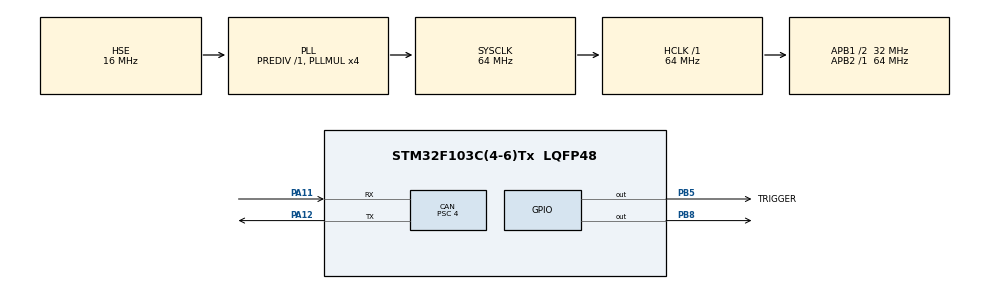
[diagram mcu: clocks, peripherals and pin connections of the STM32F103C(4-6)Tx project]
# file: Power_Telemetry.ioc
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CAN.BS1=CAN_BS1_6TQ
CAN.CalculateBaudRate=1000000
CAN.CalculateTimeBit=1000
CAN.CalculateTimeQuantum=125.0
CAN.Prescaler=4
Mcu.Family=STM32F1
Mcu.Name=STM32F103C(4-6)Tx
Mcu.Package=LQFP48
NVIC.PriorityGroup=NVIC_PRIORITYGROUP_4
PA11.Mode=CAN_Activate
PA11.Signal=CAN_RX
PA12.Mode=CAN_Activate
PA12.Signal=CAN_TX
PB5.GPIO_Label=TRIGGER
PB5.Signal=GPIO_Output
PB8.Signal=GPIO_Output
PD0-OSC_IN.Mode=HSE-External-Oscillator
PD0-OSC_IN.Signal=RCC_OSC_IN
PD1-OSC_OUT.Mode=HSE-External-Oscillator
PD1-OSC_OUT.Signal=RCC_OSC_OUT
ProjectManager.HeapSize=0x200
ProjectManager.StackSize=0x400
ProjectManager.TargetToolchain=STM32CubeIDE
RCC.AHBFreq_Value=64000000
RCC.APB1CLKDivider=RCC_HCLK_DIV2
RCC.APB1Freq_Value=32000000
RCC.APB1TimFreq_Value=64000000
RCC.APB2Freq_Value=64000000
RCC.APB2TimFreq_Value=64000000
RCC.DATA_CACHE_ENABLE=1
RCC.HCLKFreq_Value=64000000
RCC.HSE_VALUE=16000000
RCC.INSTRUCTION_CACHE_ENABLE=1
RCC.PLLMUL=RCC_PLL_MUL4
RCC.PLLSourceVirtual=RCC_PLLSOURCE_HSE
RCC.SYSCLKFreq_VALUE=64000000
RCC.SYSCLKSource=RCC_SYSCLKSOURCE_PLLCLK
RCC.USBFreq_Value=64000000
VP_SYS_VS_ND.Mode=No_Debug
board=custom

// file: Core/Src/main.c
/* USER CODE BEGIN Header */
/**
  ******************************************************************************
  * @file           : main.c
  * @brief          : Main program body
  ******************************************************************************
  * @attention
  *
  * Copyright (c) 2025 STMicroelectronics.
  * All rights reserved.
  *
  * This software is licensed under terms that can be found in the LICENSE file
  * in the root directory of this software component.
  * If no LICENSE file comes with this software, it is provided AS-IS.
  *
  ******************************************************************************
  */
/* USER CODE END Header */
#include "main.h"

CAN_HandleTypeDef hcan;

/* USER CODE BEGIN PV */
uint32_t lastTriggerTime = 0;
uint8_t triggerState = 0;  // 0 = LOW (spento), 1 = HIGH (acceso)
/* USER CODE END PV */

void SystemClock_Config(void);
static void MX_GPIO_Init(void);
static void MX_CAN_Init(void);

int main(void)
{

  /* MCU Configuration--------------------------------------------------------*/

  /* Reset of all peripherals, Initializes the Flash interface and the Systick. */
  HAL_Init();

  /* Configure the system clock */
  SystemClock_Config();

  /* Initialize all configured peripherals */
  MX_GPIO_Init();
  MX_CAN_Init();

  /* Infinite loop */
  while (1)
  {

    /* USER CODE BEGIN 3 */

    // Controlla se è passato 1 secondo dall'ultimo cambio di stato
    if (HAL_GetTick() - lastTriggerTime >= 1000)
    {
      // Cambia lo stato del pin TRIGGER ogni secondo
      if (triggerState == 0)
      {
        // Accendi il pin (HIGH) per 1 secondo
        //HAL_GPIO_WritePin(TRIGGER_GPIO_Port, TRIGGER_Pin, GPIO_PIN_SET);
        HAL_GPIO_WritePin(LED_GPIO_Port, LED_Pin, GPIO_PIN_SET);
        triggerState = 1;
      }
      else
      {
        // Spegni il pin (LOW) per 1 secondo
        //HAL_GPIO_WritePin(TRIGGER_GPIO_Port, TRIGGER_Pin, GPIO_PIN_RESET);
        HAL_GPIO_WritePin(LED_GPIO_Port, LED_Pin, GPIO_PIN_RESET);
        triggerState = 0;
      }

      // Aggiorna il tempo dell'ultimo cambio di stato
      lastTriggerTime = HAL_GetTick();
    }
  }
  /* USER CODE END 3 */
}

void SystemClock_Config(void)
{
  RCC_OscInitTypeDef RCC_OscInitStruct = {0};
  RCC_ClkInitTypeDef RCC_ClkInitStruct = {0};

  /** Initializes the RCC Oscillators according to the specified parameters
  * in the RCC_OscInitTypeDef structure.
  */
  RCC_OscInitStruct.OscillatorType = RCC_OSCILLATORTYPE_HSE;
  RCC_OscInitStruct.HSEState = RCC_HSE_ON;
  RCC_OscInitStruct.HSEPredivValue = RCC_HSE_PREDIV_DIV1;
  RCC_OscInitStruct.HSIState = RCC_HSI_ON;
  RCC_OscInitStruct.PLL.PLLState = RCC_PLL_ON;
  RCC_OscInitStruct.PLL.PLLSource = RCC_PLLSOURCE_HSE;
  RCC_OscInitStruct.PLL.PLLMUL = RCC_PLL_MUL4;
  if (HAL_RCC_OscConfig(&RCC_OscInitStruct) != HAL_OK)
  {
    Error_Handler();
  }

  /** Initializes the CPU, AHB and APB buses clocks
  */
  RCC_ClkInitStruct.ClockType = RCC_CLOCKTYPE_HCLK|RCC_CLOCKTYPE_SYSCLK
                              |RCC_CLOCKTYPE_PCLK1|RCC_CLOCKTYPE_PCLK2;
  RCC_ClkInitStruct.SYSCLKSource = RCC_SYSCLKSOURCE_PLLCLK;
  RCC_ClkInitStruct.AHBCLKDivider = RCC_SYSCLK_DIV1;
  RCC_ClkInitStruct.APB1CLKDivider = RCC_HCLK_DIV2;
  RCC_ClkInitStruct.APB2CLKDivider = RCC_HCLK_DIV1;

  if (HAL_RCC_ClockConfig(&RCC_ClkInitStruct, FLASH_LATENCY_2) != HAL_OK)
  {
    Error_Handler();
  }
}

static void MX_CAN_Init(void)
{

  hcan.Instance = CAN1;
  hcan.Init.Prescaler = 4;
  hcan.Init.Mode = CAN_MODE_NORMAL;
  hcan.Init.SyncJumpWidth = CAN_SJW_1TQ;
  hcan.Init.TimeSeg1 = CAN_BS1_6TQ;
  hcan.Init.TimeSeg2 = CAN_BS2_1TQ;
  hcan.Init.TimeTriggeredMode = DISABLE;
  hcan.Init.AutoBusOff = DISABLE;
  hcan.Init.AutoWakeUp = DISABLE;
  hcan.Init.AutoRetransmission = DISABLE;
  hcan.Init.ReceiveFifoLocked = DISABLE;
  hcan.Init.TransmitFifoPriority = DISABLE;
  if (HAL_CAN_Init(&hcan) != HAL_OK)
  {
    Error_Handler();
  }

}

static void MX_GPIO_Init(void)
{
  GPIO_InitTypeDef GPIO_InitStruct = {0};

  /* GPIO Ports Clock Enable */
  __HAL_RCC_GPIOD_CLK_ENABLE();
  __HAL_RCC_GPIOA_CLK_ENABLE();
  __HAL_RCC_GPIOB_CLK_ENABLE();

  /*Configure GPIO pin Output Level */
  HAL_GPIO_WritePin(GPIOB, TRIGGER_Pin|GPIO_PIN_8, GPIO_PIN_RESET);

  /*Configure GPIO pins : TRIGGER_Pin PB8 */
  GPIO_InitStruct.Pin = TRIGGER_Pin|GPIO_PIN_8;
  GPIO_InitStruct.Mode = GPIO_MODE_OUTPUT_PP;
  GPIO_InitStruct.Pull = GPIO_NOPULL;
  GPIO_InitStruct.Speed = GPIO_SPEED_FREQ_LOW;
  HAL_GPIO_Init(GPIOB, &GPIO_InitStruct);

}

void Error_Handler(void)
{
  __disable_irq();
  while (1)
  {
  }
}
